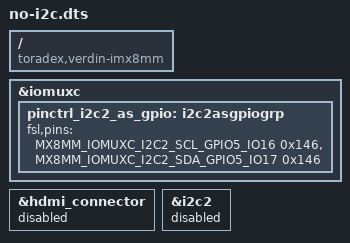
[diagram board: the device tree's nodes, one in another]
/dts-v1/;
/plugin/;

#include "imx8mm-verdin.dtsi"
#include <dt-bindings/gpio/gpio.h>
#include <dt-bindings/interrupt-controller/irq.h>

/ {
	compatible = "toradex,verdin-imx8mm";
};

&iomuxc {
	pinctrl_i2c2_as_gpio: i2c2asgpiogrp {
		fsl,pins =
			<MX8MM_IOMUXC_I2C2_SCL_GPIO5_IO16 0x146>, /* SODIMM 55 as GPIO */
			<MX8MM_IOMUXC_I2C2_SDA_GPIO5_IO17 0x146>; /* SODIMM 53 as GPIO */
	};
};

&hdmi_connector {
    status = "disabled";
};

&i2c2 {
	status = "disabled";
};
